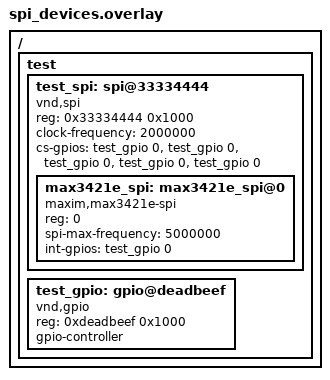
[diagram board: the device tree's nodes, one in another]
/*
 * Copyright (c) 2024 TOKITA Hiroshi
 * SPDX-License-Identifier: Apache-2.0
 */

/ {
	test {
		#address-cells = <1>;
		#size-cells = <1>;

		test_spi: spi@33334444 {
			compatible = "vnd,spi";
			reg = <0x33334444 0x1000>;
			#address-cells = <1>;
			#size-cells = <0>;
			clock-frequency = <2000000>;

			/* one entry for every devices at spi.dtsi */
			cs-gpios = <&test_gpio 0 0>,
				   <&test_gpio 0 0>,
				   <&test_gpio 0 0>,
				   <&test_gpio 0 0>,
				   <&test_gpio 0 0>;
			status = "okay";

			max3421e_spi: max3421e_spi@0 {
				compatible = "maxim,max3421e-spi";
				reg = <0>;
				spi-max-frequency = <5000000>;
				int-gpios = <&test_gpio 0 0>;
				status = "okay";
			};
		};

		test_gpio: gpio@deadbeef {
			compatible = "vnd,gpio";
			reg = <0xdeadbeef 0x1000>;
			gpio-controller;
			#gpio-cells = <0x2>;
			status = "okay";
		};
	};
};
